# STM32F469 register map
File version: 1.9
CPU: CM4 r0p1, little endian, MPU, FPU, 4 interrupt priority bits
Registers are 32-bit, read-write, reset 0x0 unless marked. A register's access mark holds for its fields unless they carry their own. Offsets are from the block's base; [hi:lo] are bit positions; lines under a group give offsets from that group; {n}, {i} and the like mark numbered series.

## RNG — Random number generator
Base 0x50060800
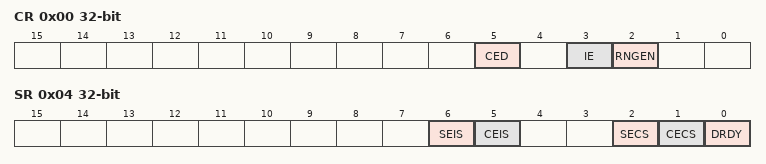
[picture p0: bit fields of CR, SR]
0x00 CR — control register
  [5] CED — Clock error detection
    0=Enabled (Clock error detection is enabled); 1=Disabled (Clock error detection is disabled)
  [3] IE — Interrupt enable
    0=Disabled (RNG interrupt is disabled); 1=Enabled (RNG interrupt is enabled)
  [2] RNGEN — Random number generator enable
    0=Disabled (Random number generator is disabled); 1=Enabled (Random number generator is enabled)
0x04 SR access per field — status register
  [6] SEIS rw write-0-clears — Seed error interrupt status
    on write: 0=Clear flag | on read: 0=No faulty sequence detected; 1=Fault (At least one faulty sequence has been detected. See **SECS** bit description for details. An interrupt is pending if IE = 1 in the RNG_CR register.)
  [5] CEIS rw write-0-clears — Clock error interrupt status
    on write: 0=Clear flag | on read: 0=Correct (The RNG clock is correct); 1=Slow (The RNG has been detected too slow An interrupt is pending if IE = 1 in the RNG_CR register)
  [2] SECS ro — Seed error current status
    0=No faulty sequence has currently been detected. If the SEIS bit is set, this means that a faulty sequence was detected and the situation has been recovered.; 1=Fault (At least one faulty sequence has been detected - see ref manual for details)
  [1] CECS ro — Clock error current status
    0=Correct (The RNG clock is correct. If the CEIS bit is set, this means that a slow clock was detected and the situation has been recovered.); 1=Slow (The RNG clock is too slow)
  [0] DRDY ro — Data ready
    0=Invalid (The RNG_DR register is not yet valid, no random data is available); 1=Valid (The RNG_DR register contains valid random data. Once the RNG_DR register has been read, this bit returns to 0 until a new random value is generated.)
0x08 DR ro — data register
  [31:0] RNDATA — Random data

## HASH — Hash processor
Base 0x50060400
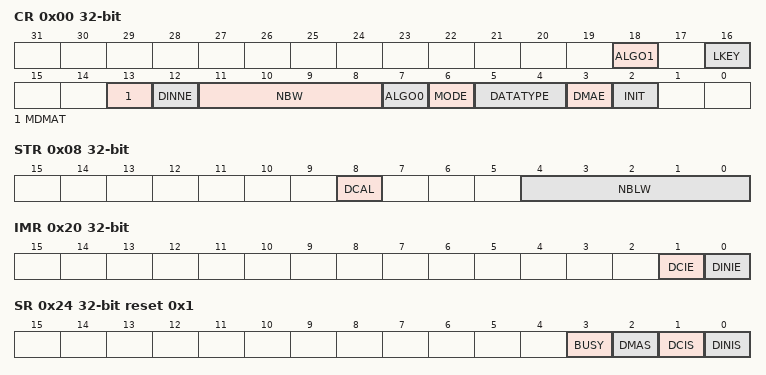
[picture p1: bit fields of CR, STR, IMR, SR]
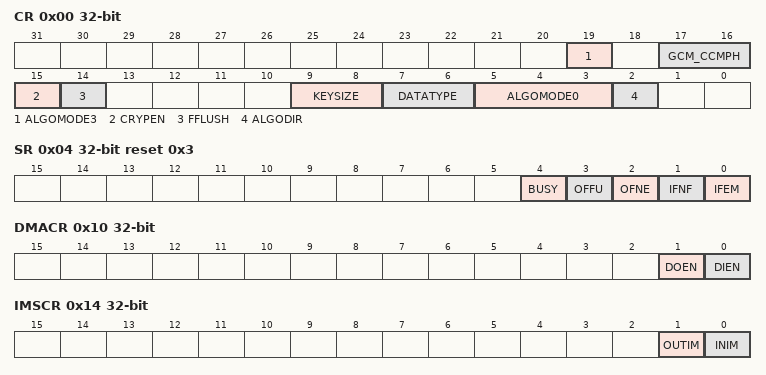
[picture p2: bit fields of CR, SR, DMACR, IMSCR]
0x00 CR access per field — control register
  [18] ALGO1 rw — ALGO
  [16] LKEY rw — Long key selection
  [13] MDMAT rw — Multiple DMA Transfers
  [12] DINNE ro — DIN not empty
  [11:8] NBW ro — Number of words already pushed
  [7] ALGO0 rw — Algorithm selection
  [6] MODE rw — Mode selection
  [5:4] DATATYPE rw — Data type selection
  [3] DMAE rw — DMA enable
  [2] INIT wo — Initialize message digest calculation
0x04 DIN — data input register
  [31:0] DATAIN — Data input
0x08 STR access per field — start register
  [8] DCAL wo — Digest calculation
  [4:0] NBLW rw — Number of valid bits in the last word of the message
{0xC+4i} HR{i} (i=0..4) ro — digest registers
  [31:0] H — H0
0x20 IMR — interrupt enable register
  [1] DCIE — Digest calculation completion interrupt enable
  [0] DINIE — Data input interrupt enable
0x24 SR access per field reset 0x1 — status register
  [3] BUSY ro — Busy bit
  [2] DMAS ro — DMA Status
  [1] DCIS rw — Digest calculation completion interrupt status
  [0] DINIS rw — Data input interrupt status
{0xF8+4i} CSR{i} (i=0..53) — context swap registers
  [31:0] CSR — CSR0
{0x310+4i} HASH_HR{i} (i=0..7) ro — HASH digest register {i}
  [31:0] H — H0

## CRYP — Cryptographic processor
Base 0x50060000
0x00 CR access per field — control register
  [19] ALGOMODE3 rw — ALGOMODE
  [17:16] GCM_CCMPH rw
  [15] CRYPEN rw — Cryptographic processor enable
  [14] FFLUSH wo — FIFO flush
  [9:8] KEYSIZE rw — Key size selection (AES mode only)
  [7:6] DATATYPE rw — Data type selection
  [5:3] ALGOMODE0 rw — Algorithm mode
  [2] ALGODIR rw — Algorithm direction
0x04 SR ro reset 0x3 — status register
  [4] BUSY — Busy bit
  [3] OFFU — Output FIFO full
  [2] OFNE — Output FIFO not empty
  [1] IFNF — Input FIFO not full
  [0] IFEM — Input FIFO empty
0x08 DIN — data input register
  [31:0] DATAIN — Data input
0x0C DOUT ro — data output register
  [31:0] DATAOUT — Data output
0x10 DMACR — DMA control register
  [1] DOEN — DMA output enable
  [0] DIEN — DMA input enable
0x14 IMSCR — interrupt mask set/clear register
  [1] OUTIM — Output FIFO service interrupt mask
  [0] INIM — Input FIFO service interrupt mask
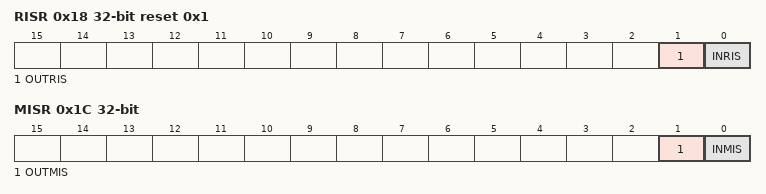
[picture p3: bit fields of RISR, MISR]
0x18 RISR ro reset 0x1 — raw interrupt status register
  [1] OUTRIS — Output FIFO service raw interrupt status
  [0] INRIS — Input FIFO service raw interrupt status
0x1C MISR ro — masked interrupt status register
  [1] OUTMIS — Output FIFO service masked interrupt status
  [0] INMIS — Input FIFO service masked interrupt status
{0x20+8i} KEY{i} (i=0..3) group — Cluster KEY{i}, containing K?LR, K?RR
  0x00 KLR wo — key registers
    [31:0] b2 — b224
  0x04 KRR wo — key registers
    [31:0] b — b192
{0x40+8i} INIT{i} (i=0..1) group — Cluster INIT{i}, containing IV?LR, IV?RR
  0x00 IVLR — initialization vector registers
    [31:0] IV — IV31
  0x04 IVRR — initialization vector registers
    [31:0] IV — IV63
{0x50+4i} CSGCMCCM{i}R (i=0..7) — context swap register
  [31:0] CSGCMCCMR — CSGCMCCM0R
{0x70+4i} CSGCM{i}R (i=0..7) — context swap register
  [31:0] CSGCMR — CSGCM0R
